# telemetry_receiver_wrap: IP-XACT component
VLNV tenstorrent.com:ocah:telemetry_receiver_wrap:1.0

## Address spaces and blocks
telemetry_receiver_wrap_mmap.telemetry_receiver_wrap: base 'h0, range 'h300, width 32

## Registers
Registers are 32-bit, read-only, reset 0x0 unless marked. A register's access mark holds for its fields unless they carry their own. Offsets are from the block's base; lines under a group give offsets from that group; [hi:lo] are bit positions; {n}, {i} and the like mark numbered series; 'fields as' and 'values as' point back to an identical list; <NAME> marks a mode.

## telemetry_receiver_wrap_mmap.telemetry_receiver_wrap — Wrapper address map instantiating the telemetry receiver channels.
Base 0x00000000
{0x0+0x100*i} telemetry_receiver[{i}] (i=0..2) group — Configuration, status, and data-buffer registers for a single telemetry receiver channel.
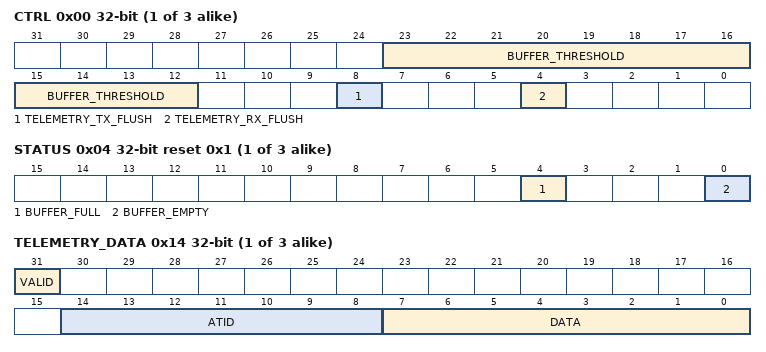
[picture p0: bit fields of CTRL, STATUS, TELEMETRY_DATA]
  0x00 CTRL access per field — Control Register
    [23:12] BUFFER_THRESHOLD rw — Telemetry Buffer Threshold. The Telemetry Buffer Threshold Interrupt is asserted when the number of beats in the buffer is greater than this value. Only values below the buffer depth can assert the interrupt.
    [8] TELEMETRY_TX_FLUSH rw — Telemetry Transmitter Flush. Writing `1` flushes all FIFOs in the telemetry transmitter. The flushing is done via the ATB AF interface. This bit clears itself when the transmitter acknowledges the flush. Writing `0` while a flush is pending withdraws the request, so other fields of this register must be updated with a read-modify-write while the bit is set. The transmitter can finish a flush only while the buffer has space, so firmware must read `TELEMETRY_DATA` while this bit is set.
    [4] TELEMETRY_RX_FLUSH wo — Telemetry Receiver Flush. Writing `1` discards all beats queued in the buffer.
  0x04 STATUS reset 0x1
    [4] BUFFER_FULL — Telemetry Buffer Full. Set when the buffer holds the maximum number of beats.
    [0] BUFFER_EMPTY — Telemetry Buffer Empty. Set when the buffer holds no beats.
  0x08 INTR_STATUS — Interrupt Status Register
    [4] BUFFER_THRESHOLD — Telemetry Buffer Threshold Interrupt. Asserted when the number of beats in the buffer is greater than `CTRL.BUFFER_THRESHOLD`.
  0x0C INTR_ENABLE rw — Interrupt Enable Register
    [4] BUFFER_THRESHOLD — Telemetry Buffer Threshold Interrupt Enable.
  0x10 INTR_TEST rw — Interrupt Test Register
    [4] BUFFER_THRESHOLD — Telemetry Buffer Threshold Interrupt Test. Writing `1` forces the interrupt and writing `0` releases it.
  0x14 TELEMETRY_DATA — Telemetry Data Register. One read returns `DATA`, `ATID` and `VALID` of the oldest beat in the buffer and removes that beat. A read while the buffer is empty returns `0x0000_0000` and removes nothing.
    [31] VALID read-modifies — Beat Valid. Set when the buffer holds a beat, so `DATA` and `ATID` are valid.
    [14:8] ATID read-modifies — ATB ID. Contains `atid` of the oldest beat in the buffer.
    [7:0] DATA read-modifies — ATB Data. Contains `atdata` of the oldest beat in the buffer.

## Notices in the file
SPDX-License-Identifier: Apache-2.0
SPDX-FileCopyrightText: 2026 Tenstorrent USA, Inc.
